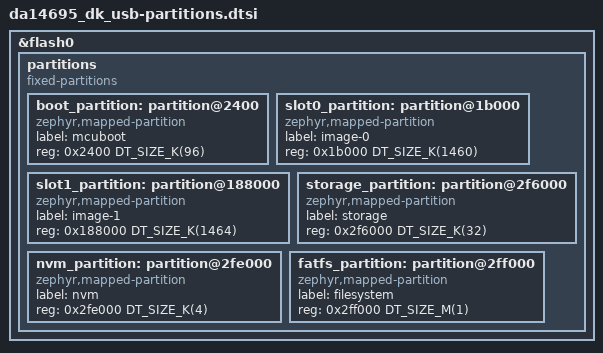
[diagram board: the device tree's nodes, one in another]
/* Partition layout for da14695_dk_usb: the flash memory map shared by the
 * bootloader and every application image. Generated by
 * tools/partition_layout.py; do not edit by hand -- re-run
 * `python3 tools/partition_layout.py --fix da14695_dk_usb` after changing
 * the upstream board geometry or tools/boards.toml.
 *
 * Board-specific overlay glue (delete-nodes, device enablement,
 * aliases/chosen) lives in dts/renesas/da14695_dk_usb.dtsi, which includes
 * this file.
 */

&flash0 {
	partitions {
		compatible = "fixed-partitions";
		#address-cells = <1>;
		#size-cells = <1>;
		ranges;

		boot_partition: partition@2400 {
			compatible = "zephyr,mapped-partition";
			label = "mcuboot";
			reg = <0x2400 DT_SIZE_K(96)>;
		};

		slot0_partition: partition@1b000 {
			compatible = "zephyr,mapped-partition";
			label = "image-0";
			reg = <0x1b000 DT_SIZE_K(1460)>;
		};

		slot1_partition: partition@188000 {
			compatible = "zephyr,mapped-partition";
			label = "image-1";
			reg = <0x188000 DT_SIZE_K(1464)>;
		};

		storage_partition: partition@2f6000 {
			compatible = "zephyr,mapped-partition";
			label = "storage";
			reg = <0x2f6000 DT_SIZE_K(32)>;
		};

		nvm_partition: partition@2fe000 {
			compatible = "zephyr,mapped-partition";
			label = "nvm";
			reg = <0x2fe000 DT_SIZE_K(4)>;
		};

		fatfs_partition: partition@2ff000 {
			compatible = "zephyr,mapped-partition";
			label = "filesystem";
			reg = <0x2ff000 DT_SIZE_M(1)>;
		};
	};
};
